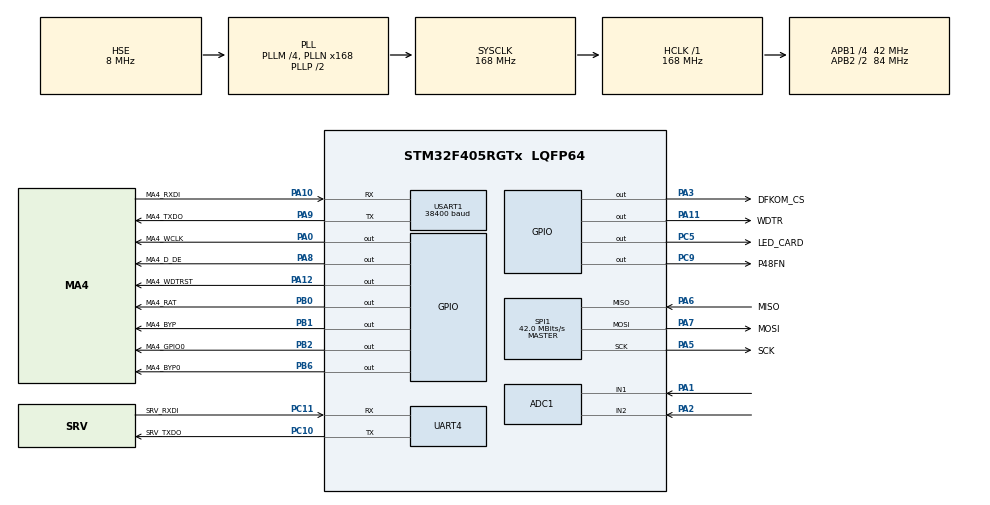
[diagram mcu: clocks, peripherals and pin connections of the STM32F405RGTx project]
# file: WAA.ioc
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ADC1.Channel-0\#ChannelRegularConversion=ADC_CHANNEL_1
ADC1.NbrOfConversionFlag=1
ADC1.Rank-0\#ChannelRegularConversion=1
ADC1.SamplingTime-0\#ChannelRegularConversion=ADC_SAMPLETIME_3CYCLES
ADC1.master=1
Mcu.Family=STM32F4
Mcu.Name=STM32F405RGTx
Mcu.Package=LQFP64
NVIC.PriorityGroup=NVIC_PRIORITYGROUP_4
NVIC.TIM1_UP_TIM10_IRQn=true\:15\:0\:false\:false\:true\:false\:true\:true
NVIC.TimeBase=TIM1_UP_TIM10_IRQn
NVIC.TimeBaseIP=TIM1
NVIC.UART4_IRQn=true\:0\:0\:false\:false\:true\:true\:true\:true
NVIC.USART1_IRQn=true\:0\:0\:false\:false\:true\:true\:true\:true
PA0-WKUP.GPIO_Label=MA4_WCLK
PA0-WKUP.Signal=GPIO_Output
PA1.Signal=ADCx_IN1
PA10.GPIO_Label=MA4_RXDI
PA10.Mode=Asynchronous
PA10.Signal=USART1_RX
PA11.GPIO_Label=WDTR
PA11.Signal=GPIO_Output
PA12.GPIO_Label=MA4_WDTRST
PA12.Signal=GPIO_Output
PA13.Signal=SYS_JTMS-SWDIO
PA14.Signal=SYS_JTCK-SWCLK
PA2.Signal=ADCx_IN2
PA3.GPIO_Label=DFKOM_CS
PA3.Signal=GPIO_Output
PA5.GPIO_Label=SCK
PA5.Mode=Full_Duplex_Master
PA5.Signal=SPI1_SCK
PA6.GPIO_Label=MISO
PA6.Mode=Full_Duplex_Master
PA6.Signal=SPI1_MISO
PA7.GPIO_Label=MOSI
PA7.Mode=Full_Duplex_Master
PA7.Signal=SPI1_MOSI
PA8.GPIO_Label=MA4_D_DE
PA8.Signal=GPIO_Output
PA9.GPIO_Label=MA4_TXDO
PA9.Mode=Asynchronous
PA9.Signal=USART1_TX
PB0.GPIO_Label=MA4_RAT
PB0.Signal=GPIO_Output
PB1.GPIO_Label=MA4_BYP
PB1.Signal=GPIO_Output
PB2.GPIO_Label=MA4_GPIO0
PB2.Signal=GPIO_Output
PB5.Signal=I2S3_SD
PB6.GPIO_Label=MA4_BYP0
PB6.Signal=GPIO_Output
PC10.GPIO_Label=SRV_TXDO
PC10.Mode=Multiprocessor_communication
PC10.Signal=UART4_TX
PC11.GPIO_Label=SRV_RXDI
PC11.Mode=Multiprocessor_communication
PC11.Signal=UART4_RX
PC5.GPIO_Label=LED_CARD
PC5.Signal=GPIO_Output
PC9.GPIO_Label=P48FN
PC9.Signal=GPIO_Output
PH0-OSC_IN.Mode=HSE-External-Oscillator
PH0-OSC_IN.Signal=RCC_OSC_IN
PH1-OSC_OUT.Mode=HSE-External-Oscillator
PH1-OSC_OUT.Signal=RCC_OSC_OUT
ProjectManager.HeapSize=0x200
ProjectManager.StackSize=0x400
ProjectManager.TargetToolchain=STM32CubeIDE
RCC.48MHZClocksFreq_Value=84000000
RCC.AHBFreq_Value=168000000
RCC.APB1CLKDivider=RCC_HCLK_DIV4
RCC.APB1Freq_Value=42000000
RCC.APB1TimFreq_Value=84000000
RCC.APB2CLKDivider=RCC_HCLK_DIV2
RCC.APB2Freq_Value=84000000
RCC.APB2TimFreq_Value=168000000
RCC.CortexFreq_Value=168000000
RCC.HCLKFreq_Value=168000000
RCC.HSE_VALUE=8000000
RCC.HSI_VALUE=16000000
RCC.LSE_VALUE=32768
RCC.PLLM=4
RCC.PLLN=168
RCC.PLLSourceVirtual=RCC_PLLSOURCE_HSE
RCC.SYSCLKFreq_VALUE=168000000
RCC.SYSCLKSource=RCC_SYSCLKSOURCE_PLLCLK
RCC.VCOOutputFreq_Value=336000000
SH.ADCx_IN1.0=ADC1_IN1,IN1
SH.ADCx_IN2.0=ADC1_IN2,IN2
SPI1.CalculateBaudRate=42.0 MBits/s
SPI1.Direction=SPI_DIRECTION_2LINES
SPI1.Mode=SPI_MODE_MASTER
SPI1.VirtualType=VM_MASTER
UART4.VirtualMode=Asynchronous
USART1.BaudRate=38400
USART1.VirtualMode=VM_ASYNC
VP_CRC_VS_CRC.Mode=CRC_Activate
VP_SYS_VS_tim1.Mode=TIM1
board=custom

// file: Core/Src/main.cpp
/* USER CODE BEGIN Header */
/**
  ******************************************************************************
  * @file           : main.c
  * @brief          : Main program body
  ******************************************************************************
  * @attention
  *
  * Copyright (c) 2022 STMicroelectronics.
  * All rights reserved.
  *
  * This software is licensed under terms that can be found in the LICENSE file
  * in the root directory of this software component.
  * If no LICENSE file comes with this software, it is provided AS-IS.
  *
  ******************************************************************************
  */
/* USER CODE END Header */
#include "main.h"
#include "adc.h"
#include "crc.h"
#include "spi.h"
#include "usart.h"
#include "gpio.h"

/* USER CODE BEGIN Includes */
#include "../Mods/RS485_E/M485_E.h"
#include "../Mods/GPIO/MGPIO.h"
/* USER CODE END Includes */

/* USER CODE BEGIN PV */
uint8_t mRXBuf[2];
/* USER CODE END PV */

void SystemClock_Config(void);

/* USER CODE BEGIN 0 */
//----------------------------------------------------------------------------
void HAL_UART_TxCpltCallback( UART_HandleTypeDef *huart ){
  //__disable_irq();
  //if( huart == g485E.mhUart   )  g485E.onIT_TX();
  //if( huart == gST7580.mhUart )  gST7580.onIT_TX();
 // __enable_irq();
 }//----------------------------------------------------------------------------

//----------------------------------------------------------------------------
void HAL_UART_RxCpltCallback(UART_HandleTypeDef *huart ) {
 // __disable_irq();
  if( huart == g485E.mhUart   )  g485E.onIT_RX();
	//HAL_GPIO_TogglePin (LED_CARD_GPIO_Port, LED_CARD_Pin);
	//HAL_UART_Receive_IT(  huart, mRXBuf, 1 );

  //if( huart == gST7580.mhUart )  gST7580.onIT_RX();
  //__enable_irq();
 }//----------------------------------------------------------------------------
/* USER CODE END 0 */

int main(void)
{

  /* MCU Configuration--------------------------------------------------------*/

  /* Reset of all peripherals, Initializes the Flash interface and the Systick. */
  HAL_Init();

  /* Configure the system clock */
  SystemClock_Config();

  /* Initialize all configured peripherals */
  MX_GPIO_Init();
  MX_ADC1_Init();
  MX_CRC_Init();
  MX_SPI1_Init();
  MX_UART4_Init();
  MX_USART1_UART_Init();
  /* USER CODE BEGIN 2 */
//  _o485E_PwrEN = 0;

  g485E.init( &huart1 );
  //_o485E_PwrEN_2 = 0;
  /* USER CODE END 2 */

  /* Infinite loop */
  /* USER CODE BEGIN WHILE */
  __enable_irq();
  while (1)
  {
    /* USER CODE END WHILE */

    /* USER CODE BEGIN 3 */
	  //HAL_GPIO_TogglePin (LED_CARD_GPIO_Port, LED_CARD_Pin);

//	  for(int i=0; i<50000;i++)
//	  {
//
//	  }
	  HAL_GPIO_TogglePin (WDTR_GPIO_Port, WDTR_Pin);
	  HAL_GPIO_TogglePin ( MA4_WDTRST_GPIO_Port, MA4_WDTRST_Pin);
	  HAL_Delay(100);
	  //g485E.sendTX_TEST();
	  //HAL_UART_Transmit_IT(&huart1,mRXBuf,1);
	  //HAL_Delay (1000);
  }
  /* USER CODE END 3 */
}

void SystemClock_Config(void)
{
  RCC_OscInitTypeDef RCC_OscInitStruct = {0};
  RCC_ClkInitTypeDef RCC_ClkInitStruct = {0};

  /** Configure the main internal regulator output voltage
  */
  __HAL_RCC_PWR_CLK_ENABLE();
  __HAL_PWR_VOLTAGESCALING_CONFIG(PWR_REGULATOR_VOLTAGE_SCALE1);

  /** Initializes the RCC Oscillators according to the specified parameters
  * in the RCC_OscInitTypeDef structure.
  */
  RCC_OscInitStruct.OscillatorType = RCC_OSCILLATORTYPE_HSE;
  RCC_OscInitStruct.HSEState = RCC_HSE_ON;
  RCC_OscInitStruct.PLL.PLLState = RCC_PLL_ON;
  RCC_OscInitStruct.PLL.PLLSource = RCC_PLLSOURCE_HSE;
  RCC_OscInitStruct.PLL.PLLM = 4;
  RCC_OscInitStruct.PLL.PLLN = 168;
  RCC_OscInitStruct.PLL.PLLP = RCC_PLLP_DIV2;
  RCC_OscInitStruct.PLL.PLLQ = 4;
  if (HAL_RCC_OscConfig(&RCC_OscInitStruct) != HAL_OK)
  {
    Error_Handler();
  }

  /** Initializes the CPU, AHB and APB buses clocks
  */
  RCC_ClkInitStruct.ClockType = RCC_CLOCKTYPE_HCLK|RCC_CLOCKTYPE_SYSCLK
                              |RCC_CLOCKTYPE_PCLK1|RCC_CLOCKTYPE_PCLK2;
  RCC_ClkInitStruct.SYSCLKSource = RCC_SYSCLKSOURCE_PLLCLK;
  RCC_ClkInitStruct.AHBCLKDivider = RCC_SYSCLK_DIV1;
  RCC_ClkInitStruct.APB1CLKDivider = RCC_HCLK_DIV4;
  RCC_ClkInitStruct.APB2CLKDivider = RCC_HCLK_DIV2;

  if (HAL_RCC_ClockConfig(&RCC_ClkInitStruct, FLASH_LATENCY_5) != HAL_OK)
  {
    Error_Handler();
  }
}

/* USER CODE BEGIN 4 */
#include "../Mods/RS485_E/M485_E_cpp.h"
#include "../Mods/RS485_E/M485_E_cpp_RX.h"
#include "../Mods/RS485_E/M485_E_cpp_TX.h"
/* USER CODE END 4 */

void HAL_TIM_PeriodElapsedCallback(TIM_HandleTypeDef *htim)
{
  if (htim->Instance == TIM1) {
    HAL_IncTick();
  }
}

void Error_Handler(void)
{
  __disable_irq();
  while (1)
  {
  }
}
